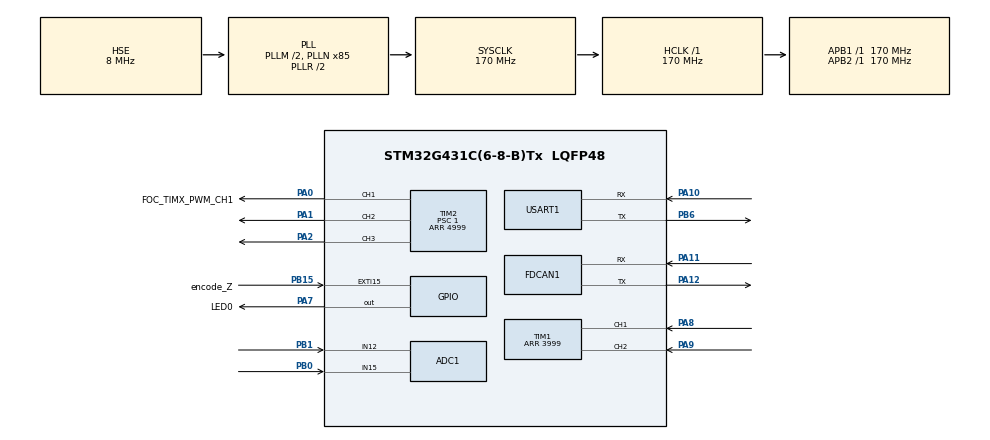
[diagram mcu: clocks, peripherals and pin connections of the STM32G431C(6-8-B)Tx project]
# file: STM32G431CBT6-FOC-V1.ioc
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ADC1.Channel-1\#ChannelRegularConversion=ADC_CHANNEL_15
ADC1.Channel-2\#ChannelRegularConversion=ADC_CHANNEL_12
ADC1.ClockPrescaler=ADC_CLOCK_ASYNC_DIV4
ADC1.ContinuousConvMode=ENABLE
ADC1.DMAContinuousRequests=ENABLE
ADC1.NbrOfConversion=2
ADC1.NbrOfConversionFlag=1
ADC1.OffsetNumber-1\#ChannelRegularConversion=ADC_OFFSET_NONE
ADC1.OffsetNumber-2\#ChannelRegularConversion=ADC_OFFSET_NONE
ADC1.Overrun=ADC_OVR_DATA_OVERWRITTEN
ADC1.Rank-1\#ChannelRegularConversion=1
ADC1.Rank-2\#ChannelRegularConversion=2
ADC1.SamplingTime-1\#ChannelRegularConversion=ADC_SAMPLETIME_12CYCLES_5
ADC1.SamplingTime-2\#ChannelRegularConversion=ADC_SAMPLETIME_12CYCLES_5
ADC1.master=1
Dma.ADC1.0.Direction=DMA_PERIPH_TO_MEMORY
Dma.ADC1.0.EventEnable=DISABLE
Dma.ADC1.0.Instance=DMA1_Channel1
Dma.ADC1.0.MemDataAlignment=DMA_MDATAALIGN_HALFWORD
Dma.ADC1.0.MemInc=DMA_MINC_ENABLE
Dma.ADC1.0.Mode=DMA_CIRCULAR
Dma.ADC1.0.PeriphDataAlignment=DMA_PDATAALIGN_HALFWORD
Dma.ADC1.0.PeriphInc=DMA_PINC_DISABLE
Dma.ADC1.0.Polarity=HAL_DMAMUX_REQ_GEN_RISING
Dma.ADC1.0.Priority=DMA_PRIORITY_MEDIUM
Dma.ADC1.0.RequestNumber=1
Dma.ADC1.0.SignalID=NONE
Dma.ADC1.0.SyncEnable=DISABLE
Dma.ADC1.0.SyncPolarity=HAL_DMAMUX_SYNC_NO_EVENT
Dma.ADC1.0.SyncRequestNumber=1
Dma.ADC1.0.SyncSignalID=NONE
Dma.Request0=ADC1
FDCAN1.AutoRetransmission=ENABLE
FDCAN1.CalculateBaudRateNominal=1000000
FDCAN1.CalculateTimeBitNominal=1000
FDCAN1.CalculateTimeQuantumNominal=100.0
FDCAN1.DataPrescaler=2
FDCAN1.DataSyncJumpWidth=2
FDCAN1.DataTimeSeg1=13
FDCAN1.DataTimeSeg2=3
FDCAN1.ExtFiltersNbr=1
FDCAN1.FrameFormat=FDCAN_FRAME_FD_BRS
FDCAN1.Mode=FDCAN_MODE_NORMAL
FDCAN1.NominalPrescaler=17
FDCAN1.NominalSyncJumpWidth=2
FDCAN1.NominalTimeSeg1=7
FDCAN1.NominalTimeSeg2=2
FDCAN1.StdFiltersNbr=1
FDCAN1.TransmitPause=DISABLE
Mcu.Family=STM32G4
Mcu.Name=STM32G431C(6-8-B)Tx
Mcu.Package=LQFP48
NVIC.DMA1_Channel1_IRQn=true\:0\:0\:false\:false\:true\:false\:true\:true
NVIC.EXTI15_10_IRQn=true\:0\:0\:false\:false\:true\:true\:true\:true
NVIC.FDCAN1_IT0_IRQn=true\:2\:0\:true\:false\:true\:true\:true\:true
NVIC.PriorityGroup=NVIC_PRIORITYGROUP_4
PA0.GPIO_Label=FOC_TIMX_PWM_CH1
PA0.GPIO_Speed=GPIO_SPEED_FREQ_HIGH
PA0.Signal=S_TIM2_CH1
PA1.GPIO_Speed=GPIO_SPEED_FREQ_HIGH
PA1.Signal=S_TIM2_CH2
PA10.GPIO_Speed=GPIO_SPEED_FREQ_HIGH
PA10.Mode=Asynchronous
PA10.Signal=USART1_RX
PA11.GPIO_Speed=GPIO_SPEED_FREQ_HIGH
PA11.Mode=FDCAN_Activate
PA11.Signal=FDCAN1_RX
PA12.GPIO_Speed=GPIO_SPEED_FREQ_HIGH
PA12.Mode=FDCAN_Activate
PA12.Signal=FDCAN1_TX
PA13.Mode=Serial_Wire
PA13.Signal=SYS_JTMS-SWDIO
PA14.Mode=Serial_Wire
PA14.Signal=SYS_JTCK-SWCLK
PA2.GPIO_Speed=GPIO_SPEED_FREQ_HIGH
PA2.Signal=S_TIM2_CH3
PA7.GPIO_Label=LED0
PA7.GPIO_Speed=GPIO_SPEED_FREQ_HIGH
PA7.PinState=GPIO_PIN_SET
PA7.Signal=GPIO_Output
PA8.GPIO_PuPd=GPIO_PULLUP
PA8.GPIO_Speed=GPIO_SPEED_FREQ_HIGH
PA8.Signal=S_TIM1_CH1
PA9.GPIO_PuPd=GPIO_PULLUP
PA9.GPIO_Speed=GPIO_SPEED_FREQ_HIGH
PA9.Signal=S_TIM1_CH2
PB0.Mode=IN15-Single-Ended
PB0.Signal=ADC1_IN15
PB1.Mode=IN12-Single-Ended
PB1.Signal=ADC1_IN12
PB15.GPIO_Label=encode_Z
PB15.Signal=GPXTI15
PB6.GPIO_Speed=GPIO_SPEED_FREQ_HIGH
PB6.Mode=Asynchronous
PB6.Signal=USART1_TX
PF0-OSC_IN.Mode=HSE-External-Oscillator
PF0-OSC_IN.Signal=RCC_OSC_IN
PF1-OSC_OUT.Mode=HSE-External-Oscillator
PF1-OSC_OUT.Signal=RCC_OSC_OUT
ProjectManager.HeapSize=0x200
ProjectManager.StackSize=0x400
ProjectManager.TargetToolchain=MDK-ARM V5.32
RCC.ADC12Freq_Value=170000000
RCC.AHBFreq_Value=170000000
RCC.APB1Freq_Value=170000000
RCC.APB1TimFreq_Value=170000000
RCC.APB2Freq_Value=170000000
RCC.APB2TimFreq_Value=170000000
RCC.CortexFreq_Value=170000000
RCC.EXTERNAL_CLOCK_VALUE=12288000
RCC.HCLKFreq_Value=170000000
RCC.HSE_VALUE=8000000
RCC.HSI48_VALUE=48000000
RCC.HSI_VALUE=16000000
RCC.LSE_VALUE=32768
RCC.PLLM=RCC_PLLM_DIV2
RCC.PLLN=85
RCC.PLLSourceVirtual=RCC_PLLSOURCE_HSE
RCC.SYSCLKFreq_VALUE=170000000
RCC.SYSCLKSource=RCC_SYSCLKSOURCE_PLLCLK
RCC.USBFreq_Value=170000000
RCC.VCOOutputFreq_Value=340000000
SH.S_TIM1_CH1.0=TIM1_CH1,Encoder_Interface
SH.S_TIM1_CH2.0=TIM1_CH2,Encoder_Interface
SH.S_TIM2_CH1.0=TIM2_CH1,PWM Generation1 CH1
SH.S_TIM2_CH2.0=TIM2_CH2,PWM Generation2 CH2
SH.S_TIM2_CH3.0=TIM2_CH3,PWM Generation3 CH3
TIM1.AutoReloadPreload=TIM_AUTORELOAD_PRELOAD_ENABLE
TIM1.EncoderMode=TIM_ENCODERMODE_TI12
TIM1.IC1Polarity=TIM_ICPOLARITY_FALLING
TIM1.IC2Polarity=TIM_ICPOLARITY_FALLING
TIM1.PeriodNoDither=3999
TIM2.AutoReloadPreload=TIM_AUTORELOAD_PRELOAD_ENABLE
TIM2.Channel-PWM\ Generation1\ CH1=TIM_CHANNEL_1
TIM2.Channel-PWM\ Generation2\ CH2=TIM_CHANNEL_2
TIM2.Channel-PWM\ Generation3\ CH3=TIM_CHANNEL_3
TIM2.PeriodNoDither=4999
TIM2.Prescaler=1
USART1.VirtualMode-Asynchronous=VM_ASYNC
VP_SYS_VS_DBSignals.Mode=DisableDeadBatterySignals
board=custom

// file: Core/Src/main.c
/* USER CODE BEGIN Header */
/**
  ******************************************************************************
  * @file           : main.c
  * @brief          : Main program body
  ******************************************************************************
  * @attention
  *
  * Copyright (c) 2025 STMicroelectronics.
  * All rights reserved.
  *
  * This software is licensed under terms that can be found in the LICENSE file
  * in the root directory of this software component.
  * If no LICENSE file comes with this software, it is provided AS-IS.
  *
  ******************************************************************************
  */
/* USER CODE END Header */
#include "main.h"
#include "adc.h"
#include "dma.h"
#include "fdcan.h"
#include "tim.h"
#include "usart.h"
#include "gpio.h"

void SystemClock_Config(void);

int main(void)
{

  /* MCU Configuration--------------------------------------------------------*/

  /* Reset of all peripherals, Initializes the Flash interface and the Systick. */
  HAL_Init();

  /* Configure the system clock */
  SystemClock_Config();

  /* USER CODE BEGIN SysInit */
    delay_init(170);
  /* USER CODE END SysInit */

  /* Initialize all configured peripherals */
  MX_GPIO_Init();
  MX_DMA_Init();
  MX_ADC1_Init();
  MX_TIM1_Init();
  MX_TIM2_Init();
  MX_USART1_UART_Init();
  MX_FDCAN1_Init();
  /* USER CODE BEGIN 2 */

    foc_init();
    motor_init_flag = 1;
    motor_target = 0;

    control_data_updata();
    zero_angle = angle_now;

    LED0(0);

  /* USER CODE END 2 */

  /* Infinite loop */
  while (1)
  {

    /* USER CODE BEGIN 3 */

//      uint8_t yu_buf[8] = {0x01, dd, 0x03, 0x04, 0x05, 0x06, 0x07, 0x08};
//      aa = fdcan_send_msg(yu_buf, FDCAN_DLC_BYTES_8);

//      foc_set_angle_velocity_current_control(motor_target);
//      printf("%f\n", angle_now);
      Taskloop_select();

//      data_feedback();

//      encoder_read();
//      read_angle_test();

//      CalSensorAngle();
//      LED0_TOGGLE();
      //delay_ms(500);

      //printf("56\n");

//      for(int i=0; i<10; i++)
//      {
//        float temp = measureLq();
//        Ld += temp;
//      }
//      Ld = Ld / 10;

      //foc_set_velocity_current_control(motor_target);

      //foc_set_velocity_current_control(motor_target);

      //res=fdcan_send_msg(tx_canbuf, FDCAN_DLC_BYTES_16);

//        tx_canbuf[0] = tx_canbuf[0] + 1;
//        if(tx_canbuf[0] > 10)
//        {
//            tx_canbuf[0] = 0;
//        }

  }
  /* USER CODE END 3 */
}

void SystemClock_Config(void)
{
  RCC_OscInitTypeDef RCC_OscInitStruct = {0};
  RCC_ClkInitTypeDef RCC_ClkInitStruct = {0};

  /** Configure the main internal regulator output voltage
  */
  HAL_PWREx_ControlVoltageScaling(PWR_REGULATOR_VOLTAGE_SCALE1_BOOST);

  /** Initializes the RCC Oscillators according to the specified parameters
  * in the RCC_OscInitTypeDef structure.
  */
  RCC_OscInitStruct.OscillatorType = RCC_OSCILLATORTYPE_HSE;
  RCC_OscInitStruct.HSEState = RCC_HSE_ON;
  RCC_OscInitStruct.PLL.PLLState = RCC_PLL_ON;
  RCC_OscInitStruct.PLL.PLLSource = RCC_PLLSOURCE_HSE;
  RCC_OscInitStruct.PLL.PLLM = RCC_PLLM_DIV2;
  RCC_OscInitStruct.PLL.PLLN = 85;
  RCC_OscInitStruct.PLL.PLLP = RCC_PLLP_DIV2;
  RCC_OscInitStruct.PLL.PLLQ = RCC_PLLQ_DIV2;
  RCC_OscInitStruct.PLL.PLLR = RCC_PLLR_DIV2;
  if (HAL_RCC_OscConfig(&RCC_OscInitStruct) != HAL_OK)
  {
    Error_Handler();
  }

  /** Initializes the CPU, AHB and APB buses clocks
  */
  RCC_ClkInitStruct.ClockType = RCC_CLOCKTYPE_HCLK|RCC_CLOCKTYPE_SYSCLK
                              |RCC_CLOCKTYPE_PCLK1|RCC_CLOCKTYPE_PCLK2;
  RCC_ClkInitStruct.SYSCLKSource = RCC_SYSCLKSOURCE_PLLCLK;
  RCC_ClkInitStruct.AHBCLKDivider = RCC_SYSCLK_DIV1;
  RCC_ClkInitStruct.APB1CLKDivider = RCC_HCLK_DIV1;
  RCC_ClkInitStruct.APB2CLKDivider = RCC_HCLK_DIV1;

  if (HAL_RCC_ClockConfig(&RCC_ClkInitStruct, FLASH_LATENCY_4) != HAL_OK)
  {
    Error_Handler();
  }
}

void Error_Handler(void)
{
  __disable_irq();
  while (1)
  {
  }
}
